LIN_description_file;
LIN_protocol_version = "J2602_1_1.0";
LIN_language_version = "J2602_3_1.0";
LIN_speed = 10.417 kbps;

Nodes {
        Master: BusMaster, 10 ms, 1 ms, 34 bits, 1 %;
        Slaves: MLX; //?? ??
}

Node_attributes {
        MLX {
                LIN_protocol = "J2602";
                configured_NAD = 0x65;
                product_id = 0x5AFE, 0xFEED, 0x01;
                response_error = RESP_ERR;
                P2_min = 0.000 ms;
                ST_min = 0.000 ms;
                configurable_frames {
                        PUB1 = 0x1300;
                        SUB1 = 0x1301;
                }
                 //response_tolerance = 35 %; ??
        }
}

Signals {
        PUB1_B0: 7, 0, MLX, BusMaster;
        PUB1_B1: 8, 0, MLX, BusMaster;

        SUB1_B0: 8, 0, BusMaster, MLX;
        SUB1_B1: 8, 0, BusMaster, MLX;
        SUB1_B2: 8, 0, BusMaster, MLX;
        SUB1_B3: 8, 0, BusMaster, MLX;
        SUB1_B4: 8, 0, BusMaster, MLX;
        SUB1_B5: 8, 0, BusMaster, MLX;
        SUB1_B6: 8, 0, BusMaster, MLX;
        SUB1_B7: 8, 0, BusMaster, MLX;

        RESP_ERR: 1, 0, MLX, BusMaster;

        PUB2_B0: 8, 0, MLX, BusMaster;
        PUB2_B1: 8, 0, MLX, BusMaster;

        SUB2_B0: 8, 0, BusMaster, MLX;
        SUB2_B1: 8, 0, BusMaster, MLX;

}

Frames {
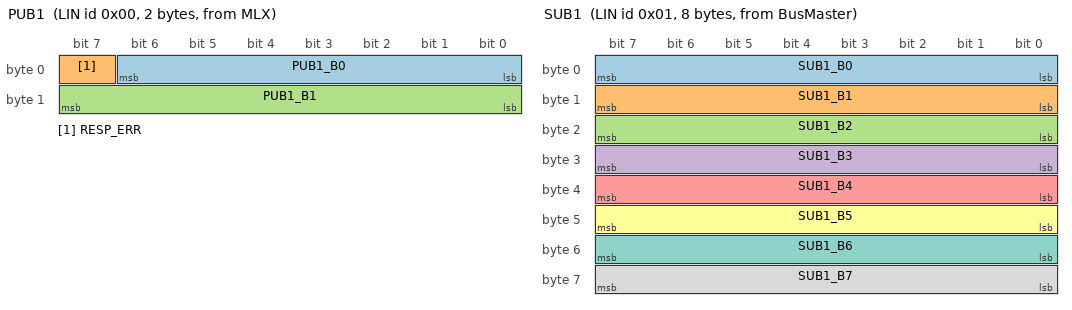
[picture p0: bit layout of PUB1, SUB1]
        PUB1 : 0x00, MLX, 2 {
                PUB1_B0, 0;
                RESP_ERR, 7;
                PUB1_B1, 8;
        }

        SUB1 : 0x01, BusMaster, 8 {
                SUB1_B0, 0;
                SUB1_B1, 8;
                SUB1_B2, 16;
                SUB1_B3, 24;
                SUB1_B4, 32;
                SUB1_B5, 40;
                SUB1_B6, 48;
                SUB1_B7, 56;
        }

        PUB2 : 0x02, MLX, 2 {
                PUB2_B0, 0;
                PUB2_B1, 8;
        }

        SUB2 : 0x03, BusMaster, 2 {
                SUB2_B0, 0;
                SUB2_B1, 8;
        }

}

Schedule_tables {
        Normal {
                PUB1 delay 20.000 ms;
                SUB1 delay 20.000 ms;

                PUB2 delay 20.000 ms;
                SUB2 delay 20.000 ms;
        }
}
